VERSION "created by canmatrix"

NS_ :

BS_:

BU_: User ADM_PC_LL25 ADM_PC_BC25 ADM_PC_BP25 ADM_PC_BI25

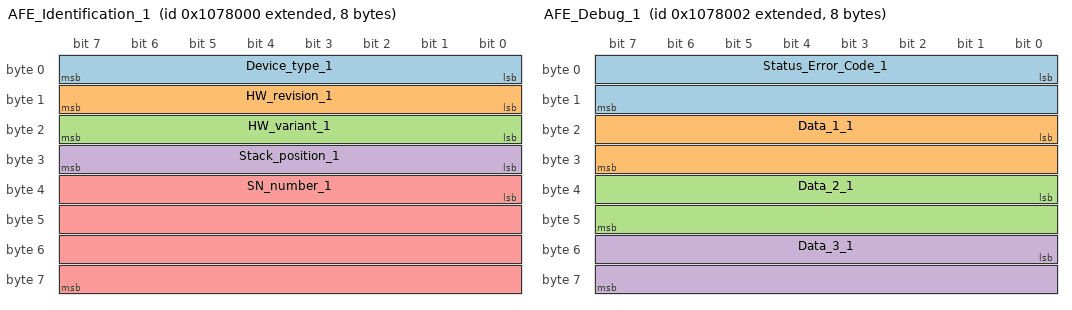
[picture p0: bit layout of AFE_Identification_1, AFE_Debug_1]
BO_ 2164752384 AFE_Identification_1: 8 ADM_PC_BP25
 SG_ Device_type_1 : 0|8@1+ (1,0) [0|255] "" Vector__XXX
 SG_ HW_revision_1 : 8|8@1+ (1,0) [0|255] "" Vector__XXX
 SG_ HW_variant_1 : 16|8@1+ (1,0) [0|255] "" Vector__XXX
 SG_ Stack_position_1 : 24|8@1+ (1,0) [0|255] "" Vector__XXX
 SG_ SN_number_1 : 32|32@1+ (1,0) [0|4294967295] "" Vector__XXX

BO_ 2164752385 AFE_FwInfo_1: 8 ADM_PC_BP25
 SG_ FW_info_mux_1 M : 56|8@1+ (1,0) [0|255] "" Vector__XXX
 SG_ FW_revision_0_1 m0 : 0|8@1+ (1,0) [0|255] "" Vector__XXX
 SG_ FW_revision_1_1 m0 : 8|8@1+ (1,0) [0|255] "" Vector__XXX
 SG_ FW_revision_2_1 m0 : 16|8@1+ (1,0) [0|255] "" Vector__XXX
 SG_ FW_revision_3_1 m0 : 24|8@1+ (1,0) [0|255] "" Vector__XXX
 SG_ FW_revision_4_1 m0 : 32|8@1+ (1,0) [0|255] "" Vector__XXX
 SG_ FW_revision_5_1 m0 : 40|8@1+ (1,0) [0|255] "" Vector__XXX
 SG_ FW_revision_6_1 m0 : 48|8@1+ (1,0) [0|255] "" Vector__XXX
 SG_ FW_revision_7_1 m1 : 0|8@1+ (1,0) [0|255] "" Vector__XXX
 SG_ FW_revision_8_1 m1 : 8|8@1+ (1,0) [0|255] "" Vector__XXX
 SG_ FW_revision_9_1 m1 : 16|8@1+ (1,0) [0|255] "" Vector__XXX
 SG_ FW_revision_10_1 m1 : 24|8@1+ (1,0) [0|255] "" Vector__XXX
 SG_ FW_revision_11_1 m1 : 32|8@1+ (1,0) [0|255] "" Vector__XXX
 SG_ FW_revision_12_1 m1 : 40|8@1+ (1,0) [0|255] "" Vector__XXX
 SG_ FW_revision_13_1 m1 : 48|8@1+ (1,0) [0|255] "" Vector__XXX
 SG_ FW_datecode_0_1 m2 : 0|8@1+ (1,0) [0|255] "" Vector__XXX
 SG_ FW_datecode_1_1 m2 : 8|8@1+ (1,0) [0|255] "" Vector__XXX
 SG_ FW_datecode_2_1 m2 : 16|8@1+ (1,0) [0|255] "" Vector__XXX
 SG_ FW_datecode_3_1 m2 : 24|8@1+ (1,0) [0|255] "" Vector__XXX
 SG_ FW_datecode_4_1 m2 : 32|8@1+ (1,0) [0|255] "" Vector__XXX
 SG_ FW_datecode_5_1 m2 : 40|8@1+ (1,0) [0|255] "" Vector__XXX
 SG_ FW_datecode_6_1 m2 : 48|8@1+ (1,0) [0|255] "" Vector__XXX
 SG_ FW_datecode_7_1 m3 : 0|8@1+ (1,0) [0|255] "" Vector__XXX
 SG_ FW_datecode_8_1 m3 : 8|8@1+ (1,0) [0|255] "" Vector__XXX
 SG_ FW_datecode_9_1 m3 : 16|8@1+ (1,0) [0|255] "" Vector__XXX
 SG_ FW_datecode_10_1 m3 : 24|8@1+ (1,0) [0|255] "" Vector__XXX
 SG_ FW_datecode_11_1 m3 : 32|8@1+ (1,0) [0|255] "" Vector__XXX
 SG_ FW_datecode_12_1 m3 : 40|8@1+ (1,0) [0|255] "" Vector__XXX
 SG_ FW_datecode_13_1 m3 : 48|8@1+ (1,0) [0|255] "" Vector__XXX

BO_ 2164752397 _AFE_Boot_FwInfo_1: 8 ADM_PC_BP25
 SG_ Boot_FW_info_mux_1 M : 56|8@1+ (1,0) [0|255] "" Vector__XXX
 SG_ FW_revision_0_1 m0 : 0|8@1+ (1,0) [0|255] "" Vector__XXX
 SG_ FW_revision_1_1 m0 : 8|8@1+ (1,0) [0|255] "" Vector__XXX
 SG_ FW_revision_2_1 m0 : 16|8@1+ (1,0) [0|255] "" Vector__XXX
 SG_ FW_revision_3_1 m0 : 24|8@1+ (1,0) [0|255] "" Vector__XXX
 SG_ FW_revision_4_1 m0 : 32|8@1+ (1,0) [0|255] "" Vector__XXX
 SG_ FW_revision_5_1 m0 : 40|8@1+ (1,0) [0|255] "" Vector__XXX
 SG_ FW_revision_6_1 m0 : 48|8@1+ (1,0) [0|255] "" Vector__XXX
 SG_ FW_revision_7_1 m1 : 0|8@1+ (1,0) [0|255] "" Vector__XXX
 SG_ FW_revision_8_1 m1 : 8|8@1+ (1,0) [0|255] "" Vector__XXX
 SG_ FW_revision_9_1 m1 : 16|8@1+ (1,0) [0|255] "" Vector__XXX
 SG_ FW_revision_10_1 m1 : 24|8@1+ (1,0) [0|255] "" Vector__XXX
 SG_ FW_revision_11_1 m1 : 32|8@1+ (1,0) [0|255] "" Vector__XXX
 SG_ FW_revision_12_1 m1 : 40|8@1+ (1,0) [0|255] "" Vector__XXX
 SG_ FW_revision_13_1 m1 : 48|8@1+ (1,0) [0|255] "" Vector__XXX
 SG_ FW_datecode_0_1 m2 : 0|8@1+ (1,0) [0|255] "" Vector__XXX
 SG_ FW_datecode_1_1 m2 : 8|8@1+ (1,0) [0|255] "" Vector__XXX
 SG_ FW_datecode_2_1 m2 : 16|8@1+ (1,0) [0|255] "" Vector__XXX
 SG_ FW_datecode_3_1 m2 : 24|8@1+ (1,0) [0|255] "" Vector__XXX
 SG_ FW_datecode_4_1 m2 : 32|8@1+ (1,0) [0|255] "" Vector__XXX
 SG_ FW_datecode_5_1 m2 : 40|8@1+ (1,0) [0|255] "" Vector__XXX
 SG_ FW_datecode_6_1 m2 : 48|8@1+ (1,0) [0|255] "" Vector__XXX
 SG_ FW_datecode_7_1 m3 : 0|8@1+ (1,0) [0|255] "" Vector__XXX
 SG_ FW_datecode_8_1 m3 : 8|8@1+ (1,0) [0|255] "" Vector__XXX
 SG_ FW_datecode_9_1 m3 : 16|8@1+ (1,0) [0|255] "" Vector__XXX
 SG_ FW_datecode_10_1 m3 : 24|8@1+ (1,0) [0|255] "" Vector__XXX
 SG_ FW_datecode_11_1 m3 : 32|8@1+ (1,0) [0|255] "" Vector__XXX
 SG_ FW_datecode_12_1 m3 : 40|8@1+ (1,0) [0|255] "" Vector__XXX
 SG_ FW_datecode_13_1 m3 : 48|8@1+ (1,0) [0|255] "" Vector__XXX

BO_ 2164752386 AFE_Debug_1: 8 ADM_PC_BP25
 SG_ Status_Error_Code_1 : 0|16@1+ (1,0) [0|65535] "" Vector__XXX
 SG_ Data_1_1 : 16|16@1+ (1,0) [0|65535] "" Vector__XXX
 SG_ Data_2_1 : 32|16@1+ (1,0) [0|65535] "" Vector__XXX
 SG_ Data_3_1 : 48|16@1+ (1,0) [0|65535] "" Vector__XXX

BO_ 2164752391 AFE_Status_1: 8 ADM_PC_BP25
 SG_ Running_1 : 0|1@1+ (1,0) [0|1] "" Vector__XXX
 SG_ PWM_1 : 1|1@1+ (1,0) [0|1] "" Vector__XXX
 SG_ Current_dc_loop_mode_1 : 2|1@1+ (1,0) [0|1] "" Vector__XXX
 SG_ Current_ac_loop_mode_1 : 3|1@1+ (1,0) [0|1] "" Vector__XXX
 SG_ Buck_1 : 5|1@1+ (1,0) [0|1] "" Vector__XXX
 SG_ Boost_1 : 6|1@1+ (1,0) [0|1] "" Vector__XXX
 SG_ Precharge_dc_buck_mode_1 : 7|1@1+ (1,0) [0|1] "" Vector__XXX
 SG_ Precharge_dc_boost_mode_1 : 8|1@1+ (1,0) [0|1] "" Vector__XXX
 SG_ Rectifier_3ph_1 : 9|1@1+ (1,0) [0|1] "" Vector__XXX
 SG_ Stack_mode_1 : 10|1@1+ (1,0) [0|1] "" Vector__XXX
 SG_ Master_1 : 11|1@1+ (1,0) [0|1] "" Vector__XXX
 SG_ Slave_1 : 12|1@1+ (1,0) [0|1] "" Vector__XXX
 SG_ Inverter_1ph_1 : 13|1@1+ (1,0) [0|1] "" Vector__XXX
 SG_ Boost_Neutral_1 : 14|1@1+ (1,0) [0|1] "" Vector__XXX
 SG_ Rectifier_1ph_1 : 15|1@1+ (1,0) [0|1] "" Vector__XXX
 SG_ Inverter_3ph_1 : 16|1@1+ (1,0) [0|1] "" Vector__XXX
 SG_ Ready_1 : 17|1@1+ (1,0) [0|1] "" Vector__XXX
 SG_ Inverter_1ph_Sync_1 : 18|1@1+ (1,0) [0|1] "" Vector__XXX
 SG_ Neutral_1 : 19|1@1+ (1,0) [0|1] "" Vector__XXX
 SG_ Rectifier_1ph_Buck_1 : 20|1@1+ (1,0) [0|1] "" Vector__XXX
 SG_ Inverter_1ph_Boost_1 : 21|1@1+ (1,0) [0|1] "" Vector__XXX
 SG_ Rectifier_distributed_1 : 22|1@1+ (1,0) [0|1] "" Vector__XXX
 SG_ MPPT_buck_1 : 23|1@1+ (1,0) [0|1] "" Vector__XXX
 SG_ MPPT_boost_1 : 24|1@1+ (1,0) [0|1] "" Vector__XXX
 SG_ Buck_2p_float_1 : 25|1@1+ (1,0) [0|1] "" Vector__XXX
 SG_ Inverter_1ph_Distributed_1 : 26|1@1+ (1,0) [0|1] "" Vector__XXX

BO_ 2164752390 AFE_Faults_1: 3 ADM_PC_BP25
 SG_ Protection_trip_internal_1 : 0|1@1+ (1,0) [0|1] "" Vector__XXX
 SG_ Protection_trip_external_1 : 1|1@1+ (1,0) [0|1] "" Vector__XXX
 SG_ Phase_U_overcurrent_1 : 2|1@1+ (1,0) [0|1] "" Vector__XXX
 SG_ Phase_U_overvoltage_1 : 3|1@1+ (1,0) [0|1] "" Vector__XXX
 SG_ Phase_U_undervoltage_1 : 4|1@1+ (1,0) [0|1] "" Vector__XXX
 SG_ Phase_V_overvoltage_1 : 5|1@1+ (1,0) [0|1] "" Vector__XXX
 SG_ Phase_V_undervoltage_1 : 6|1@1+ (1,0) [0|1] "" Vector__XXX
 SG_ Phase_V_overcurrent_1 : 7|1@1+ (1,0) [0|1] "" Vector__XXX
 SG_ Phase_W_overvoltage_1 : 8|1@1+ (1,0) [0|1] "" Vector__XXX
 SG_ Phase_W_undervoltage_1 : 9|1@1+ (1,0) [0|1] "" Vector__XXX
 SG_ Phase_W_overcurrent_1 : 10|1@1+ (1,0) [0|1] "" Vector__XXX
 SG_ DC_undervoltage_1 : 11|1@1+ (1,0) [0|1] "" Vector__XXX
 SG_ DC_overvoltage_1 : 12|1@1+ (1,0) [0|1] "" Vector__XXX
 SG_ MOSFET_overtemperature_1 : 13|1@1+ (1,0) [0|1] "" Vector__XXX
 SG_ Inductor_overtemperature_1 : 14|1@1+ (1,0) [0|1] "" Vector__XXX
 SG_ Keep_Alive_not_served_1 : 15|1@1+ (1,0) [0|1] "" Vector__XXX
 SG_ PLL_not_locked_1 : 16|1@1+ (1,0) [0|1] "" Vector__XXX
 SG_ NFO_1 : 20|1@1+ (1,0) [0|1] "" Vector__XXX
 SG_ Measurement_system_failure_1 : 21|1@1+ (1,0) [0|1] "" Vector__XXX
 SG_ EEPROM_failure_1 : 22|1@1+ (1,0) [0|1] "" Vector__XXX
 SG_ System_1 : 23|1@1+ (1,0) [0|1] "" Vector__XXX

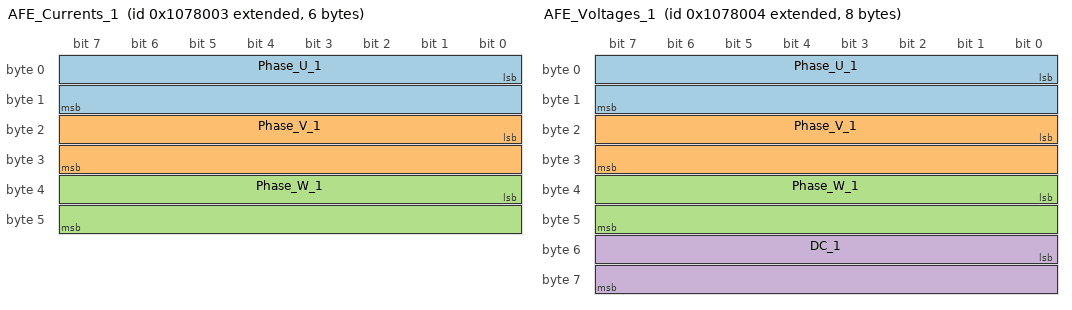
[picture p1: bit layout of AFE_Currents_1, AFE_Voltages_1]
BO_ 2164752387 AFE_Currents_1: 6 ADM_PC_BP25
 SG_ Phase_U_1 : 0|16@1- (0.01,0) [-327.68|327.67] "A" Vector__XXX
 SG_ Phase_V_1 : 16|16@1- (0.01,0) [-327.68|327.67] "A" Vector__XXX
 SG_ Phase_W_1 : 32|16@1- (0.01,0) [-327.68|327.67] "A" Vector__XXX

BO_ 2164752400 AFE_DC_Bus_current_1: 2 ADM_PC_BP25
 SG_ Bus_current_1 : 0|16@1- (0.01,0) [-327.68|327.67] "A" Vector__XXX

BO_ 2164752398 _AFE_Broadcast_1: 8 ADM_PC_BP25
 SG_ Diagnostics_Index_1 M : 56|8@1+ (1,0) [0|255] "" Vector__XXX
 SG_ Phase_U_1 m1 : 8|16@1- (0.01,0) [-327.68|327.67] "A" ADM_PC_BP25
 SG_ Phase_V_1 m1 : 24|16@1- (0.01,0) [-327.68|327.67] "A" ADM_PC_BP25
 SG_ Phase_W_1 m1 : 40|16@1- (0.01,0) [-327.68|327.67] "A" ADM_PC_BP25
 SG_ Stack_position_1 : 0|5@1+ (1,0) [0|31] "" ADM_PC_BP25
 SG_ Group_ID_1 : 5|3@1+ (1,0) [0|7] "" ADM_PC_BP25

BO_ 2164752388 AFE_Voltages_1: 8 ADM_PC_BP25
 SG_ Phase_U_1 : 0|16@1- (0.1,0) [-3276.8|3276.7] "V" Vector__XXX
 SG_ Phase_V_1 : 16|16@1- (0.1,0) [-3276.8|3276.7] "V" Vector__XXX
 SG_ Phase_W_1 : 32|16@1- (0.1,0) [-3276.8|3276.7] "V" Vector__XXX
 SG_ DC_1 : 48|16@1- (0.1,0) [-3276.8|3276.7] "V" Vector__XXX

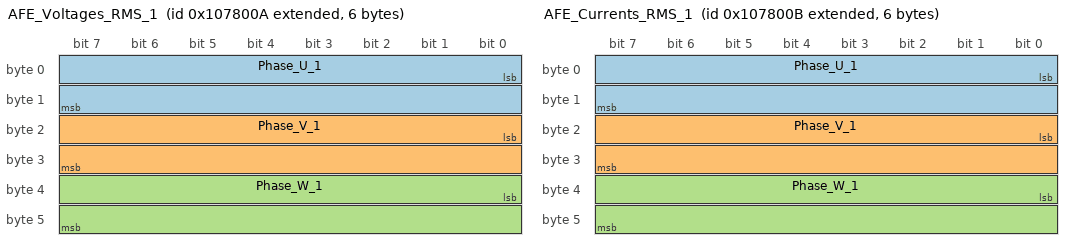
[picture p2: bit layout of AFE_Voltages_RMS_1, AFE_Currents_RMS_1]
BO_ 2164752394 AFE_Voltages_RMS_1: 6 ADM_PC_BP25
 SG_ Phase_U_1 : 0|16@1+ (0.1,0) [0|6553.5] "V" Vector__XXX
 SG_ Phase_V_1 : 16|16@1+ (0.1,0) [0|6553.5] "V" Vector__XXX
 SG_ Phase_W_1 : 32|16@1+ (0.1,0) [0|6553.5] "V" Vector__XXX

BO_ 2164752395 AFE_Currents_RMS_1: 6 ADM_PC_BP25
 SG_ Phase_U_1 : 0|16@1+ (0.01,0) [0.00|655.35] "A" Vector__XXX
 SG_ Phase_V_1 : 16|16@1+ (0.01,0) [0.00|655.35] "A" Vector__XXX
 SG_ Phase_W_1 : 32|16@1+ (0.01,0) [0.00|655.35] "A" Vector__XXX

BO_ 2164752396 AFE_Mains_1: 4 ADM_PC_BP25
 SG_ Frequency_1 : 0|16@1+ (0.01,0) [0.00|655.35] "Hz" Vector__XXX
 SG_ Phase_1 : 16|16@1- (0.1,0) [-3276.8|3276.7] "Deg." Vector__XXX

BO_ 2164752389 AFE_Temperatures_1: 4 ADM_PC_BP25
 SG_ Temp_Bridge_1 : 0|16@1- (0.01,0) [-327.68|327.67] "°C" Vector__XXX
 SG_ Temp_Inductors_1 : 16|16@1- (0.01,0) [-327.68|327.67] "°C" Vector__XXX

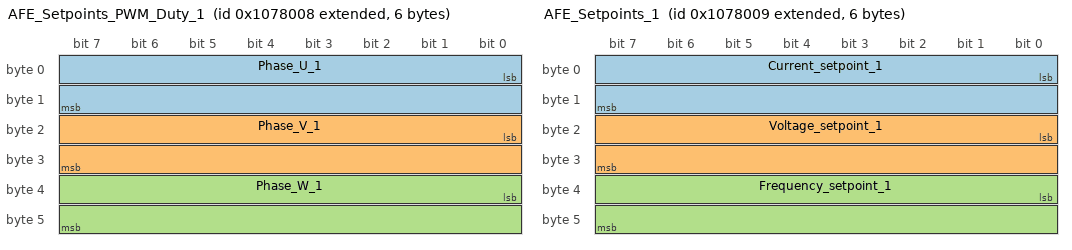
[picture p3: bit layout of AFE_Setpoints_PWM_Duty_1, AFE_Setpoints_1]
BO_ 2164752392 AFE_Setpoints_PWM_Duty_1: 6 ADM_PC_BP25
 SG_ Phase_U_1 : 0|16@1+ (0.001525902,0) [0E-009|99.999987570] "%" Vector__XXX
 SG_ Phase_V_1 : 16|16@1+ (0.001525902,0) [0E-009|99.999987570] "%" Vector__XXX
 SG_ Phase_W_1 : 32|16@1+ (0.001525902,0) [0E-009|99.999987570] "%" Vector__XXX

BO_ 2164752393 AFE_Setpoints_1: 6 ADM_PC_BP25
 SG_ Current_setpoint_1 : 0|16@1- (0.01,0) [-327.68|327.67] "A" Vector__XXX
 SG_ Voltage_setpoint_1 : 16|16@1+ (0.1,0) [0|6553.5] "V" Vector__XXX
 SG_ Frequency_setpoint_1 : 32|16@1+ (0.01,0) [0.00|655.35] "Hz" Vector__XXX

BO_ 2164719712 AFE_Keep_Alive_1: 1 User
 SG_ Keep_Alive_Enable_1 : 0|1@1+ (1,0) [0|1] "" ADM_PC_BP25

BO_ 2164719680 AFE_Mode_Control_1: 8 User
 SG_ Converter_ON_1 : 0|1@1+ (1,0) [0|1] "" ADM_PC_BP25
 SG_ PWM_ON_1 : 1|1@1+ (1,0) [0|1] "" ADM_PC_BP25
 SG_ DC_Current_feedback_ON_1 : 2|1@1+ (1,0) [0|1] "" ADM_PC_BP25
 SG_ AC_Current_feedback_ON_1 : 3|1@1+ (1,0) [0|1] "" ADM_PC_BP25
 SG_ Buck_ON_1 : 5|1@1+ (1,0) [0|1] "" ADM_PC_BP25
 SG_ Boost_ON_1 : 6|1@1+ (1,0) [0|1] "" ADM_PC_BP25
 SG_ Rectifier_3ph_ON_1 : 9|1@1+ (1,0) [0|1] "" ADM_PC_BP25
 SG_ Inverter_1ph_ON_1 : 10|1@1+ (1,0) [0|1] "" ADM_PC_BP25
 SG_ Rectifier_1ph_ON_1 : 11|1@1+ (1,0) [0|1] "" ADM_PC_BP25
 SG_ Boost_Neutral_ON_1 : 12|1@1+ (1,0) [0|1] "" ADM_PC_BP25
 SG_ Inverter_3ph_ON_1 : 13|1@1+ (1,0) [0|1] "" ADM_PC_BP25
 SG_ Inverter_1ph_Sync_ON_1 : 14|1@1+ (1,0) [0|1] "" ADM_PC_BP25
 SG_ Neutral_ON_1 : 15|1@1+ (1,0) [0|1] "" ADM_PC_BP25
 SG_ Rectifier_1ph_Buck_ON_1 : 16|1@1+ (1,0) [0|1] "" ADM_PC_BP25
 SG_ Inverter_1ph_Boost_ON_1 : 17|1@1+ (1,0) [0|1] "" ADM_PC_BP25
 SG_ Rectifier_Distributed_ON_1 : 18|1@1+ (1,0) [0|1] "" ADM_PC_BP25
 SG_ MPPT_buck_ON_1 : 19|1@1+ (1,0) [0|1] "" ADM_PC_BP25
 SG_ MPPT_boost_ON_1 : 20|1@1+ (1,0) [0|1] "" ADM_PC_BP25
 SG_ Buck_2p_float_ON_1 : 21|1@1+ (1,0) [0|1] "" ADM_PC_BP25
 SG_ Inverter_1ph_Distributed_ON_1 : 22|1@1+ (1,0) [0|1] "" ADM_PC_BP25

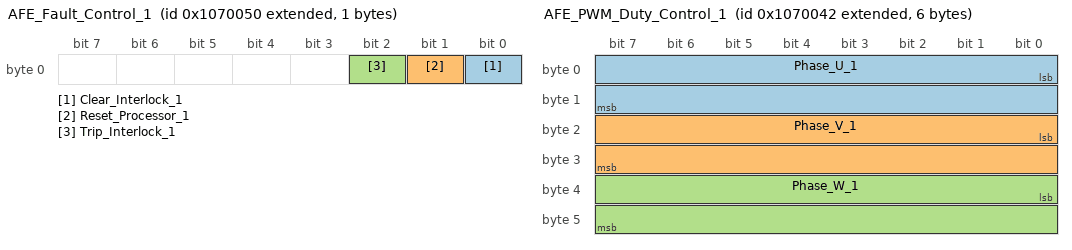
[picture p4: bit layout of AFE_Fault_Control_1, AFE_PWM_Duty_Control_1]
BO_ 2164719696 AFE_Fault_Control_1: 1 User
 SG_ Clear_Interlock_1 : 0|1@1+ (1,0) [0|1] "" ADM_PC_BP25
 SG_ Reset_Processor_1 : 1|1@1+ (1,0) [0|1] "" ADM_PC_BP25
 SG_ Trip_Interlock_1 : 2|1@1+ (1,0) [0|1] "" ADM_PC_BP25

BO_ 2164719681 AFE_Reactive_Current_Setpoint_Co: 2 User
 SG_ Reactive_current_setpoint_1 : 0|16@1- (0.01,0) [-150|150] "A" ADM_PC_BP25

BO_ 2164719682 AFE_PWM_Duty_Control_1: 6 User
 SG_ Phase_U_1 : 0|16@1+ (0.001525902,0) [0E-009|99.999987570] "%" ADM_PC_BP25
 SG_ Phase_V_1 : 16|16@1+ (0.001525902,0) [0E-009|99.999987570] "%" ADM_PC_BP25
 SG_ Phase_W_1 : 32|16@1+ (0.001525902,0) [0E-009|99.999987570] "%" ADM_PC_BP25

BO_ 2164719683 AFE_Current_Setpoint_Control_1: 2 User
 SG_ Current_setpoint_1 : 0|16@1- (0.01,0) [-150|150] "A" ADM_PC_BP25

BO_ 2164719684 AFE_Voltage_Setpoint_Control_1: 2 User
 SG_ Voltage_setpoint_1 : 0|16@1+ (0.1,0) [0|1500] "V" ADM_PC_BP25

BO_ 2164719688 AFE_Frequency_Setpoint_Control_1: 2 User
 SG_ Frequency_setpoint_1 : 0|16@1+ (0.01,0) [40|70] "Hz" ADM_PC_BP25

BO_ 2164719689 AFE_Phase_Setpoint_Control_1: 2 User
 SG_ Phase_setpoint_1 : 0|16@1+ (1,0) [0|360] "deg" ADM_PC_BP25

BO_ 2164719728 AFE_Rectifier_Setpoint_Control_1: 8 User
 SG_ Voltage_setpoint_2_1 : 0|16@1+ (0.1,0) [0|1500] "V" ADM_PC_BP25
 SG_ Current_setpoint_2_1 : 16|16@1- (0.01,0) [-150|150] "A" ADM_PC_BP25

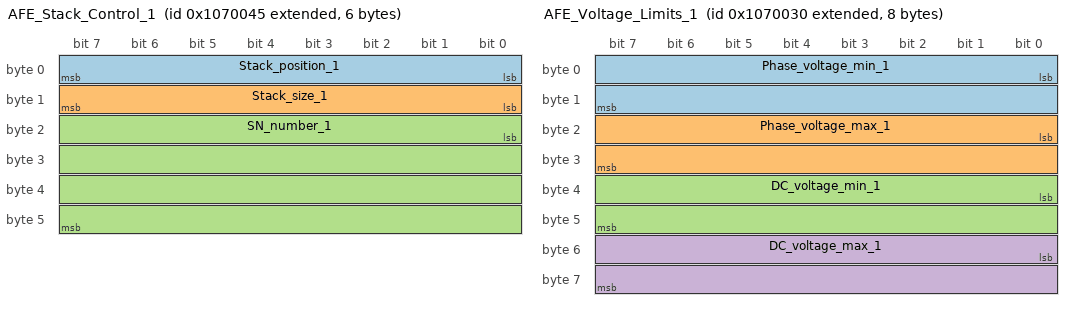
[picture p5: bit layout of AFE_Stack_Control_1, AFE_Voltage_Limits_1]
BO_ 2164719685 AFE_Stack_Control_1: 6 User
 SG_ Stack_position_1 : 0|8@1+ (1,0) [0|255] "" ADM_PC_BP25
 SG_ Stack_size_1 : 8|8@1+ (1,0) [0|255] "" ADM_PC_BP25
 SG_ SN_number_1 : 16|32@1+ (1,0) [0|4294967295] "" ADM_PC_BP25

BO_ 2164719664 AFE_Voltage_Limits_1: 8 User
 SG_ Phase_voltage_min_1 : 0|16@1- (0.1,0) [0|3276.7] "V" ADM_PC_BP25
 SG_ Phase_voltage_max_1 : 16|16@1- (0.1,0) [-3276.8|850] "V" ADM_PC_BP25
 SG_ DC_voltage_min_1 : 32|16@1- (0.1,0) [0|3276.7] "V" ADM_PC_BP25
 SG_ DC_voltage_max_1 : 48|16@1- (0.1,0) [-3276.8|850] "V" ADM_PC_BP25

BO_ 2164719665 AFE_Current_Limits_1: 4 User
 SG_ Phase_current_min_1 : 0|16@1- (0.01,0) [-60|60] "A" ADM_PC_BP25
 SG_ Phase_current_max_1 : 16|16@1- (0.01,0) [-60|60] "A" ADM_PC_BP25

BO_ 2164719692 AFE_Group_Control_1: 1 User
 SG_ Group_ID_1 : 0|8@1+ (1,0) [0|255] "" ADM_PC_BP25

BO_ 2164752399 AFE_Group_Info_1: 1 ADM_PC_BP25
 SG_ Group_ID_1 : 0|8@1+ (1,0) [0|255] "" Vector__XXX

BO_ 2164719713 AFE_System_Flags_Control_1: 8 User
 SG_ Factory_mode_1 : 0|1@1+ (1,0) [0|1] "" ADM_PC_BP25
 SG_ Silent_CAN_mode_1 : 1|1@1+ (1,0) [0|1] "" ADM_PC_BP25

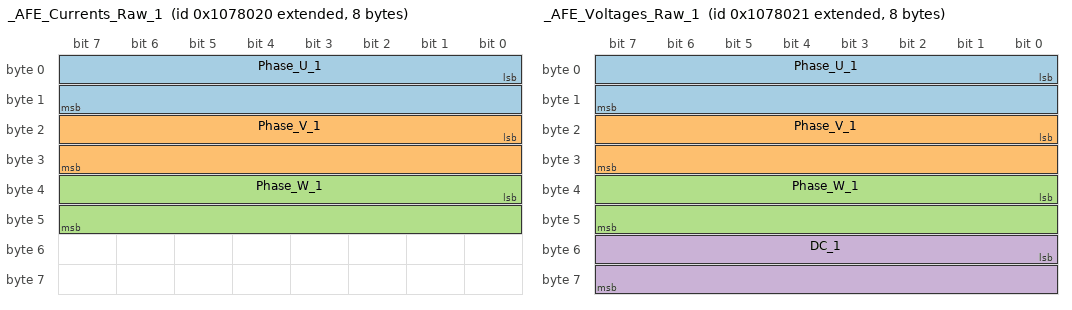
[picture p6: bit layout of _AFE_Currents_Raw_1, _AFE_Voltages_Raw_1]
BO_ 2164752416 _AFE_Currents_Raw_1: 8 ADM_PC_BP25
 SG_ Phase_U_1 : 0|16@1- (1,0) [-32768|32767] "" Vector__XXX
 SG_ Phase_V_1 : 16|16@1- (1,0) [-32768|32767] "" Vector__XXX
 SG_ Phase_W_1 : 32|16@1- (1,0) [-32768|32767] "" Vector__XXX

BO_ 2164752417 _AFE_Voltages_Raw_1: 8 ADM_PC_BP25
 SG_ Phase_U_1 : 0|16@1- (1,0) [-32768|32767] "" Vector__XXX
 SG_ Phase_V_1 : 16|16@1- (1,0) [-32768|32767] "" Vector__XXX
 SG_ Phase_W_1 : 32|16@1- (1,0) [-32768|32767] "" Vector__XXX
 SG_ DC_1 : 48|16@1- (1,0) [-32768|32767] "" Vector__XXX

BO_ 2164719690 _AFE_ADC_Calibration_Mode_1: 1 User
 SG_ Calibration_Index_1 M : 2|5@1+ (1,0) [0|31] "" Vector__XXX
 SG_ Current_U_1 m1 : 0|2@1+ (1,0) [0|3] "" ADM_PC_BP25
 SG_ Current_V_1 m2 : 0|2@1+ (1,0) [0|3] "" ADM_PC_BP25
 SG_ Current_W_1 m3 : 0|2@1+ (1,0) [0|3] "" ADM_PC_BP25
 SG_ Voltage_U_1 m4 : 0|2@1+ (1,0) [0|3] "" ADM_PC_BP25
 SG_ Voltage_V_1 m5 : 0|2@1+ (1,0) [0|3] "" ADM_PC_BP25
 SG_ Voltage_W_1 m6 : 0|2@1+ (1,0) [0|3] "" ADM_PC_BP25
 SG_ Voltage_DC_1 m7 : 0|2@1+ (1,0) [0|3] "" ADM_PC_BP25
 SG_ start_1 : 7|1@1+ (1,0) [0|1] "" ADM_PC_BP25

BO_ 2164719691 _AFE_ADC_Calibration_Setpoint_1: 3 User
 SG_ Calibration_Index_1 M : 16|5@1+ (1,0) [0|31] "" Vector__XXX
 SG_ Current_U_1 m1 : 0|16@1- (0.01,0) [-100|100] "A" ADM_PC_BP25
 SG_ Current_V_1 m2 : 0|16@1- (0.01,0) [-100|100] "A" ADM_PC_BP25
 SG_ Current_W_1 m3 : 0|16@1- (0.01,0) [-100|100] "A" ADM_PC_BP25
 SG_ Voltage_U_1 m4 : 0|16@1+ (0.1,0) [0|1500] "V" ADM_PC_BP25
 SG_ Voltage_V_1 m5 : 0|16@1+ (0.1,0) [0|1500] "V" ADM_PC_BP25
 SG_ Voltage_W_1 m6 : 0|16@1+ (0.1,0) [0|1500] "V" ADM_PC_BP25
 SG_ Voltage_DC_1 m7 : 0|16@1+ (0.1,0) [0|1500] "V" ADM_PC_BP25
 SG_ point_1 : 21|3@1+ (1,0) [0|7] "" ADM_PC_BP25

BO_ 2164719686 _AFE_Calibration_Offset_Update_1: 6 User
 SG_ Calibration_Index_1 M : 16|16@1+ (1,0) [0|65535] "" Vector__XXX
 SG_ Current_U_1 m0 : 0|16@1- (1,0) [-32768|32767] "ADC Counts" ADM_PC_BP25
 SG_ Current_V_1 m1 : 0|16@1- (1,0) [-32768|32767] "ADC Counts" ADM_PC_BP25
 SG_ Current_W_1 m2 : 0|16@1- (1,0) [-32768|32767] "ADC Counts" ADM_PC_BP25
 SG_ Voltage_U_1 m3 : 0|16@1- (1,0) [-32768|32767] "ADC Counts" ADM_PC_BP25
 SG_ Voltage_V_1 m4 : 0|16@1- (1,0) [-32768|32767] "ADC Counts" ADM_PC_BP25
 SG_ Voltage_W_1 m5 : 0|16@1- (1,0) [-32768|32767] "ADC Counts" ADM_PC_BP25
 SG_ Voltage_DC_1 m6 : 0|16@1- (1,0) [-32768|32767] "ADC Counts" ADM_PC_BP25
 SG_ CRC_1 : 32|16@1+ (1,0) [0|65535] "-" ADM_PC_BP25

BO_ 2164719687 _AFE_Calibration_Scale_Update_1: 6 User
 SG_ Calibration_Index_1 M : 16|16@1+ (1,0) [0|65535] "" Vector__XXX
 SG_ Current_U_1 m0 : 0|16@1- (0.0000152587890625,0) [-0.5000000000000000|0.4999847412109375] "scale = 1.0 + value" ADM_PC_BP25
 SG_ Current_V_1 m1 : 0|16@1- (0.0000152587890625,0) [-0.5000000000000000|0.4999847412109375] "scale = 1.0 + value" ADM_PC_BP25
 SG_ Current_W_1 m2 : 0|16@1- (0.0000152587890625,0) [-0.5000000000000000|0.4999847412109375] "scale = 1.0 + value" ADM_PC_BP25
 SG_ Voltage_U_1 m3 : 0|16@1- (0.0000152587890625,0) [-0.5000000000000000|0.4999847412109375] "scale = 1.0 + value" ADM_PC_BP25
 SG_ Voltage_V_1 m4 : 0|16@1- (0.0000152587890625,0) [-0.5000000000000000|0.4999847412109375] "scale = 1.0 + value" ADM_PC_BP25
 SG_ Voltage_W_1 m5 : 0|16@1- (0.0000152587890625,0) [-0.5000000000000000|0.4999847412109375] "scale = 1.0 + value" ADM_PC_BP25
 SG_ Voltage_DC_1 m6 : 0|16@1- (0.0000152587890625,0) [-0.5000000000000000|0.4999847412109375] "scale = 1.0 + value" ADM_PC_BP25
 SG_ CRC_1 : 32|16@1+ (1,0) [0|65535] "-" ADM_PC_BP25

BO_ 2164752465 _AFE_Calibration_Adc_Scale_1: 6 ADM_PC_BP25
 SG_ Adc_Index_1 M : 32|16@1+ (1,0) [0|65535] "" Vector__XXX
 SG_ Current_U_1 m0 : 0|32@1+ (1,0) [0|4294967295] "1 / adc_bins" User
 SG_ Current_V_1 m1 : 0|32@1+ (1,0) [0|4294967295] "1 / adc_bins" User
 SG_ Current_W_1 m2 : 0|32@1+ (1,0) [0|4294967295] "1 / adc_bins" User
 SG_ Voltage_U_1 m3 : 0|32@1+ (1,0) [0|4294967295] "1 / adc_bins" User
 SG_ Voltage_V_1 m4 : 0|32@1+ (1,0) [0|4294967295] "1 / adc_bins" User
 SG_ Voltage_W_1 m5 : 0|32@1+ (1,0) [0|4294967295] "1 / adc_bins" User
 SG_ Voltage_DC_1 m6 : 0|32@1+ (1,0) [0|4294967295] "1 / adc_bins" User

BO_ 2164752466 _AFE_Calibration_Adc_Fs_1: 6 ADM_PC_BP25
 SG_ Adc_Index_1 M : 32|16@1+ (1,0) [0|65535] "" Vector__XXX
 SG_ Current_U_1 m0 : 0|32@1+ (1,0) [0|4294967295] "Fullscale" User
 SG_ Current_V_1 m1 : 0|32@1+ (1,0) [0|4294967295] "Fullscale" User
 SG_ Current_W_1 m2 : 0|32@1+ (1,0) [0|4294967295] "Fullscale" User
 SG_ Voltage_U_1 m3 : 0|32@1+ (1,0) [0|4294967295] "Fullscale" User
 SG_ Voltage_V_1 m4 : 0|32@1+ (1,0) [0|4294967295] "Fullscale" User
 SG_ Voltage_W_1 m5 : 0|32@1+ (1,0) [0|4294967295] "Fullscale" User
 SG_ Voltage_DC_1 m6 : 0|32@1+ (1,0) [0|4294967295] "Fullscale" User

BO_ 2164752467 _AFE_Calibration_Adc_Offset_1: 4 ADM_PC_BP25
 SG_ Adc_Index_1 M : 16|16@1+ (1,0) [0|65535] "" Vector__XXX
 SG_ Current_U_1 m0 : 0|16@1- (1,0) [-32768|32767] "-" User
 SG_ Current_V_1 m1 : 0|16@1- (1,0) [-32768|32767] "-" User
 SG_ Current_W_1 m2 : 0|16@1- (1,0) [-32768|32767] "-" User
 SG_ Voltage_U_1 m3 : 0|16@1- (1,0) [-32768|32767] "-" User
 SG_ Voltage_V_1 m4 : 0|16@1- (1,0) [-32768|32767] "-" User
 SG_ Voltage_W_1 m5 : 0|16@1- (1,0) [-32768|32767] "-" User
 SG_ Voltage_DC_1 m6 : 0|16@1- (1,0) [-32768|32767] "-" User

BO_ 2164752468 _AFE_Calibration_Adc_Gain_1: 4 ADM_PC_BP25
 SG_ Adc_Index_1 M : 16|16@1+ (1,0) [0|65535] "" Vector__XXX
 SG_ Current_U_1 m0 : 0|16@1- (1,0) [-32768|32767] "-" User
 SG_ Current_V_1 m1 : 0|16@1- (1,0) [-32768|32767] "-" User
 SG_ Current_W_1 m2 : 0|16@1- (1,0) [-32768|32767] "-" User
 SG_ Voltage_U_1 m3 : 0|16@1- (1,0) [-32768|32767] "-" User
 SG_ Voltage_V_1 m4 : 0|16@1- (1,0) [-32768|32767] "-" User
 SG_ Voltage_W_1 m5 : 0|16@1- (1,0) [-32768|32767] "-" User
 SG_ Voltage_DC_1 m6 : 0|16@1- (1,0) [-32768|32767] "-" User

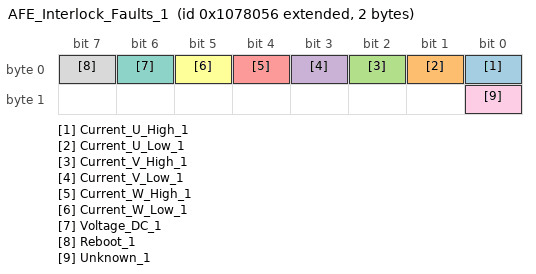
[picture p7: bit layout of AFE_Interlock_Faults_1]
BO_ 2164752470 AFE_Interlock_Faults_1: 2 ADM_PC_BP25
 SG_ Current_U_High_1 : 0|1@1+ (1,0) [0|1] "" Vector__XXX
 SG_ Current_U_Low_1 : 1|1@1+ (1,0) [0|1] "" Vector__XXX
 SG_ Current_V_High_1 : 2|1@1+ (1,0) [0|1] "" Vector__XXX
 SG_ Current_V_Low_1 : 3|1@1+ (1,0) [0|1] "" Vector__XXX
 SG_ Current_W_High_1 : 4|1@1+ (1,0) [0|1] "" Vector__XXX
 SG_ Current_W_Low_1 : 5|1@1+ (1,0) [0|1] "" Vector__XXX
 SG_ Voltage_DC_1 : 6|1@1+ (1,0) [0|1] "" Vector__XXX
 SG_ Reboot_1 : 7|1@1+ (1,0) [0|1] "" Vector__XXX
 SG_ Unknown_1 : 8|1@1+ (1,0) [0|1] "" Vector__XXX

BO_TX_BU_ 2164719680 : User,ADM_PC_LL25,ADM_PC_BC25,ADM_PC_BI25;
BO_TX_BU_ 2164719683 : User,ADM_PC_LL25,ADM_PC_BC25,ADM_PC_BI25;
BO_TX_BU_ 2164719684 : User,ADM_PC_LL25,ADM_PC_BC25,ADM_PC_BI25;
CM_ BO_ 2164752384  "Identification of the device";
CM_ BO_ 2164752385  "Git revision of the DSP firmware";
CM_ BO_ 2164752397  "Git revision of the bootloader firmware.";
CM_ BO_ 2164752386  "Values for debugging of HW/SW problems";
CM_ BO_ 2164752391  "Status bitfield";
CM_ BO_ 2164752390  "Fault bitfield";
CM_ BO_ 2164752387  "Current of phases U, V, W";
CM_ BO_ 2164752400  "Current of of the DC Bus";
CM_ BO_ 2164752398  "All AFEs will listen to this message";
CM_ BO_ 2164752395  "RMS Current of phases U, V, W";
CM_ BO_ 2164752396  "Three-Phase mains health (frequency, phase...)";
CM_ BO_ 2164752389  "Readouts of the module temperature sensors";
CM_ BO_ 2164752392  "Setpoints";
CM_ BO_ 2164752393  "Setpoints";
CM_ BO_ 2164719712  "Keep alive ping message. ";
CM_ BO_ 2164719680  "Operation Mode control: sets the converter operation mode";
CM_ BO_ 2164719696  "Fault Control: actions to clear faults and reset the system";
CM_ BO_ 2164719681  "Reactive power setpoint control.";
CM_ BO_ 2164719682  "PWM duty cycle control";
CM_ BO_ 2164719683  "Current setpoint control";
CM_ BO_ 2164719684  "Voltage setpoint control";
CM_ BO_ 2164719688  "Frequency setpoint control";
CM_ BO_ 2164719689  "Phase setpoint control";
CM_ BO_ 2164719728  "Additional voltage and current setpoints in single-phase rectifier and inverter control modes.";
CM_ BO_ 2164719685  "PFC stack control";
CM_ BO_ 2164719664  "Set the input and output voltage limits (minimum and maximum)";
CM_ BO_ 2164719665  "Set the output current limits (mminimum and maximum)";
CM_ BO_ 2164719692  "Set the Group ID of the device";
CM_ BO_ 2164752399  "Contains the Group ID of the device";
CM_ BO_ 2164719713  "Control the system flags";
CM_ BO_ 2164752416  "Current of phases A and B";
CM_ BO_ 2164752417  "Current of phases A and B";
CM_ BO_ 2164719690  "Automatic ADC calibration.";
CM_ BO_ 2164719691  "Setpoint for automatic ADC calibration.";
CM_ BO_ 2164719686  "Update of the calibration table for offsets.";
CM_ BO_ 2164719687  "Update of the calibration table for scales.";
CM_ BO_ 2164752465  "
                Adc scale (resolution) value of readouts.
            ";
CM_ BO_ 2164752466  "
                Adc fullscale value of readouts.
            ";
CM_ BO_ 2164752467  "
                Readout of ADC calibration data (offset) from EEPROM.
            ";
CM_ BO_ 2164752468  "
                Readout of ADC calibration data (gain) from EEPROM.
            ";
CM_ BO_ 2164752470  "Fault bitfield";

CM_ SG_ 2164752384 Device_type_1 "The device identification field, uniquely identifies the sender in the network";
CM_ SG_ 2164752384 HW_revision_1 "The hardware revision number";
CM_ SG_ 2164752384 HW_variant_1 "The DSP firmware revision number";
CM_ SG_ 2164752384 Stack_position_1 "Position of the module within the stack";
CM_ SG_ 2164752384 SN_number_1 "Unique module serial number";
CM_ SG_ 2164752385 FW_revision_0_1 "Character 0";
CM_ SG_ 2164752385 FW_revision_1_1 "Character 1";
CM_ SG_ 2164752385 FW_revision_2_1 "Character 2";
CM_ SG_ 2164752385 FW_revision_3_1 "Character 3";
CM_ SG_ 2164752385 FW_revision_4_1 "Character 3";
CM_ SG_ 2164752385 FW_revision_5_1 "Character 3";
CM_ SG_ 2164752385 FW_revision_6_1 "Character 3";
CM_ SG_ 2164752385 FW_revision_7_1 "Character 7";
CM_ SG_ 2164752385 FW_revision_8_1 "Character 8";
CM_ SG_ 2164752385 FW_revision_9_1 "Character 9";
CM_ SG_ 2164752385 FW_revision_10_1 "Character 10";
CM_ SG_ 2164752385 FW_revision_11_1 "Character 11";
CM_ SG_ 2164752385 FW_revision_12_1 "Character 12";
CM_ SG_ 2164752385 FW_revision_13_1 "Character 13";
CM_ SG_ 2164752385 FW_datecode_0_1 "Character 0";
CM_ SG_ 2164752385 FW_datecode_1_1 "Character 1";
CM_ SG_ 2164752385 FW_datecode_2_1 "Character 2";
CM_ SG_ 2164752385 FW_datecode_3_1 "Character 3";
CM_ SG_ 2164752385 FW_datecode_4_1 "Character 3";
CM_ SG_ 2164752385 FW_datecode_5_1 "Character 3";
CM_ SG_ 2164752385 FW_datecode_6_1 "Character 3";
CM_ SG_ 2164752385 FW_datecode_7_1 "Character 7";
CM_ SG_ 2164752385 FW_datecode_8_1 "Character 8";
CM_ SG_ 2164752385 FW_datecode_9_1 "Character 9";
CM_ SG_ 2164752385 FW_datecode_10_1 "Character 10";
CM_ SG_ 2164752385 FW_datecode_11_1 "Character 11";
CM_ SG_ 2164752385 FW_datecode_12_1 "Character 12";
CM_ SG_ 2164752385 FW_datecode_13_1 "Character 13";
CM_ SG_ 2164752397 FW_revision_0_1 "Character 0";
CM_ SG_ 2164752397 FW_revision_1_1 "Character 1";
CM_ SG_ 2164752397 FW_revision_2_1 "Character 2";
CM_ SG_ 2164752397 FW_revision_3_1 "Character 3";
CM_ SG_ 2164752397 FW_revision_4_1 "Character 3";
CM_ SG_ 2164752397 FW_revision_5_1 "Character 3";
CM_ SG_ 2164752397 FW_revision_6_1 "Character 3";
CM_ SG_ 2164752397 FW_revision_7_1 "Character 7";
CM_ SG_ 2164752397 FW_revision_8_1 "Character 8";
CM_ SG_ 2164752397 FW_revision_9_1 "Character 9";
CM_ SG_ 2164752397 FW_revision_10_1 "Character 10";
CM_ SG_ 2164752397 FW_revision_11_1 "Character 11";
CM_ SG_ 2164752397 FW_revision_12_1 "Character 12";
CM_ SG_ 2164752397 FW_revision_13_1 "Character 13";
CM_ SG_ 2164752397 FW_datecode_0_1 "Character 0";
CM_ SG_ 2164752397 FW_datecode_1_1 "Character 1";
CM_ SG_ 2164752397 FW_datecode_2_1 "Character 2";
CM_ SG_ 2164752397 FW_datecode_3_1 "Character 3";
CM_ SG_ 2164752397 FW_datecode_4_1 "Character 3";
CM_ SG_ 2164752397 FW_datecode_5_1 "Character 3";
CM_ SG_ 2164752397 FW_datecode_6_1 "Character 3";
CM_ SG_ 2164752397 FW_datecode_7_1 "Character 7";
CM_ SG_ 2164752397 FW_datecode_8_1 "Character 8";
CM_ SG_ 2164752397 FW_datecode_9_1 "Character 9";
CM_ SG_ 2164752397 FW_datecode_10_1 "Character 10";
CM_ SG_ 2164752397 FW_datecode_11_1 "Character 11";
CM_ SG_ 2164752397 FW_datecode_12_1 "Character 12";
CM_ SG_ 2164752397 FW_datecode_13_1 "Character 13";
CM_ SG_ 2164752386 Status_Error_Code_1 "Main status / error code as defined in errno/errno.h";
CM_ SG_ 2164752386 Data_1_1 "Additional information for the error/status";
CM_ SG_ 2164752386 Data_2_1 "Additional information for the error/status";
CM_ SG_ 2164752386 Data_3_1 "Additional information for the error/status";
CM_ SG_ 2164752391 Running_1 "Indicates if converter is running.";
CM_ SG_ 2164752391 PWM_1 "Indicates if converter is in PWM control mode.";
CM_ SG_ 2164752391 Current_dc_loop_mode_1 "Indicates if the current DC loop is enabled.";
CM_ SG_ 2164752391 Current_ac_loop_mode_1 "Indicates if the current AC loop is enabled.";
CM_ SG_ 2164752391 Buck_1 "Indicates if converter is in buck control mode.";
CM_ SG_ 2164752391 Boost_1 "Indicates if converter is in boost control mode.";
CM_ SG_ 2164752391 Precharge_dc_buck_mode_1 "Indicates if the precharge DC mode is enabled - buck direction.";
CM_ SG_ 2164752391 Precharge_dc_boost_mode_1 "Indicates if the precharge DC mode is enabled - boost direction.";
CM_ SG_ 2164752391 Rectifier_3ph_1 "Indicates if converter is in three-phase rectifier control mode.";
CM_ SG_ 2164752391 Stack_mode_1 "Indicates if converter is operating in stack mode.";
CM_ SG_ 2164752391 Master_1 "Indicates if converter is master in the stack.";
CM_ SG_ 2164752391 Slave_1 "Indicates if converter is slave in the stack.";
CM_ SG_ 2164752391 Inverter_1ph_1 "Indicates if converter is in single-phase inverter control mode.";
CM_ SG_ 2164752391 Boost_Neutral_1 "Indicates if converter is in boost control mode with neutral generation.";
CM_ SG_ 2164752391 Rectifier_1ph_1 "Indicates if converter is in single-phase rectifier control mode.";
CM_ SG_ 2164752391 Inverter_3ph_1 "Indicates if converter is in three-phase inverter control mode.";
CM_ SG_ 2164752391 Ready_1 "Indicates if converter is ready for operation.";
CM_ SG_ 2164752391 Inverter_1ph_Sync_1 "Single-phase inverter control mode with phase synchronization.";
CM_ SG_ 2164752391 Neutral_1 "Open-loop neutral generation.";
CM_ SG_ 2164752391 Rectifier_1ph_Buck_1 "Single-phase rectifier with buck on one leg.";
CM_ SG_ 2164752391 Inverter_1ph_Boost_1 "Single-phase inverter with boost on one leg.";
CM_ SG_ 2164752391 Rectifier_distributed_1 "Not available at the moment";
CM_ SG_ 2164752391 MPPT_buck_1 "Not available at the moment";
CM_ SG_ 2164752391 MPPT_boost_1 "Not available at the moment";
CM_ SG_ 2164752391 Buck_2p_float_1 "Buck in phases L1 and L2. Phase L3 is left floating (high impedance)";
CM_ SG_ 2164752391 Inverter_1ph_Distributed_1 "Single-phase inverter mode  distributed";
CM_ SG_ 2164752390 Protection_trip_internal_1 "This flagg is asserted if the interlock is open due to an internal fault condition (self-protection)";
CM_ SG_ 2164752390 Protection_trip_external_1 "This flag is asserted if the interlock is open due to an external condition received in the module.";
CM_ SG_ 2164752390 Phase_U_overcurrent_1 "Indicates an overcurrent event on Phase U. The overcurrent event is triggered when the measured phase current is over the programmed current limit.";
CM_ SG_ 2164752390 Phase_U_overvoltage_1 "Indicates an overvoltage event on Phase U. The overvoltage event is triggered when the measured phase voltage is over the programmed voltage limit.";
CM_ SG_ 2164752390 Phase_U_undervoltage_1 "Indicates an undervoltage event on Phase U. The overvoltage event is triggered when the measured phase voltage is over the programmed voltage limit.";
CM_ SG_ 2164752390 Phase_V_overvoltage_1 "Indicates an overvoltage event on Phase V. The overvoltage event is triggered when the measured phase voltage is over the programmed voltage limit.";
CM_ SG_ 2164752390 Phase_V_undervoltage_1 "Indicates an undervoltage event on Phase U. The overvoltage event is triggered when the measured phase voltage is over the programmed voltage limit.";
CM_ SG_ 2164752390 Phase_V_overcurrent_1 "Indicates an overcurrent event on Phase U. The overcurrent event is triggered when the measured phase current is over the programmed current limit.";
CM_ SG_ 2164752390 Phase_W_overvoltage_1 "Indicates an overvoltage event on Phase U. The overvoltage event is triggered when the measured phase voltage is over the programmed voltage limit.";
CM_ SG_ 2164752390 Phase_W_undervoltage_1 "Indicates an undervoltage event on Phase U. The overvoltage event is triggered when the measured phase voltage is over the programmed voltage limit.";
CM_ SG_ 2164752390 Phase_W_overcurrent_1 "Indicates an overcurrent event on Phase U. The overcurrent event is triggered when the measured phase current is over the programmed current limit.";
CM_ SG_ 2164752390 DC_undervoltage_1 "DC bus undervoltage condition. The undervoltage condition is asserted when the measured dc bus voltage is under the programmed voltage limit.";
CM_ SG_ 2164752390 DC_overvoltage_1 "DC bus overvoltage condition. The overvoltage condition is asserted when the measured dc bus voltage is over the programmed voltage limit.";
CM_ SG_ 2164752390 MOSFET_overtemperature_1 "This flag is asserted when the temperature of the MOSFET block is too high.";
CM_ SG_ 2164752390 Inductor_overtemperature_1 "This flag is asserted when the temperature of the inductor block is too high.";
CM_ SG_ 2164752390 Keep_Alive_not_served_1 "The Keep Alive feature is enabled but it was not served with the periodic message.";
CM_ SG_ 2164752390 PLL_not_locked_1 "Flag asserted when in rectifier modes, the PLL went out of lock condition";
CM_ SG_ 2164752390 Measurement_system_failure_1 "The voltages/currents measurement system is malfunctionning, and readouts are not guaranteed to be accurate.";
CM_ SG_ 2164752390 EEPROM_failure_1 "The configuration EEPROM failed to load or save the module configuration.";
CM_ SG_ 2164752387 Phase_U_1 "Phase current is the MOSFET loop current, in the branch U of the converter.";
CM_ SG_ 2164752387 Phase_V_1 "Phase current is the MOSFET loop current, in the branch V of the converter.";
CM_ SG_ 2164752387 Phase_W_1 "Phase current is the MOSFET loop current, in the branch W of the converter.";
CM_ SG_ 2164752400 Bus_current_1 "DC Bus current is possitive when current goes from input to output";
CM_ SG_ 2164752398 Phase_U_1 "Phase current is the MOSFET loop current, in the branch U of the converter.";
CM_ SG_ 2164752398 Phase_V_1 "Phase current is the MOSFET loop current, in the branch V of the converter.";
CM_ SG_ 2164752398 Phase_W_1 "Phase current is the MOSFET loop current, in the branch W of the converter.";
CM_ SG_ 2164752398 Stack_position_1 "Sender Stack position";
CM_ SG_ 2164752398 Group_ID_1 "Sender Group ID";
CM_ SG_ 2164752395 Phase_U_1 "RMS Phase current is the MOSFET loop current, in the branch U of the converter.";
CM_ SG_ 2164752395 Phase_V_1 "RMS Phase current is the MOSFET loop current, in the branch V of the converter.";
CM_ SG_ 2164752395 Phase_W_1 "RMS Phase current is the MOSFET loop current, in the branch W of the converter.";
CM_ SG_ 2164752396 Frequency_1 "Frequency of Three-Phase system";
CM_ SG_ 2164752396 Phase_1 "Phase of Three-Phase system";
CM_ SG_ 2164752389 Temp_Bridge_1 "Temperature of the MOSFET block";
CM_ SG_ 2164752389 Temp_Inductors_1 "Temperature of the inductors";
CM_ SG_ 2164752392 Phase_U_1 "The actual PWM duty cycle setpoint";
CM_ SG_ 2164752392 Phase_V_1 "The actual PWM duty cycle setpoint";
CM_ SG_ 2164752392 Phase_W_1 "The actual PWM duty cycle setpoint";
CM_ SG_ 2164752393 Current_setpoint_1 "The actual current setpoint";
CM_ SG_ 2164752393 Voltage_setpoint_1 "The actual voltage setpoint";
CM_ SG_ 2164752393 Frequency_setpoint_1 "The actual frequency setpoint";
CM_ SG_ 2164719712 Keep_Alive_Enable_1 "If set to 1, module will expect to receive this message every second repeatedly, or it will stop operation";
CM_ SG_ 2164719680 Converter_ON_1 "Enable the converter.";
CM_ SG_ 2164719680 PWM_ON_1 "Enable the PWM control mode.";
CM_ SG_ 2164719680 DC_Current_feedback_ON_1 "Enable the DC current loop";
CM_ SG_ 2164719680 AC_Current_feedback_ON_1 "Enable the AC current loop";
CM_ SG_ 2164719680 Buck_ON_1 "Enable the buck control mode.";
CM_ SG_ 2164719680 Boost_ON_1 "Enable the boost control mode.";
CM_ SG_ 2164719680 Rectifier_3ph_ON_1 "Enable the three-phase rectifier control mode.";
CM_ SG_ 2164719680 Inverter_1ph_ON_1 "Enable the single-phase inverter control mode.";
CM_ SG_ 2164719680 Rectifier_1ph_ON_1 "Enable the single-phase rectifier control mode.";
CM_ SG_ 2164719680 Boost_Neutral_ON_1 "Enable the boost control mode with neutral generation.";
CM_ SG_ 2164719680 Inverter_3ph_ON_1 "Enable the three-phase inverter control mode.";
CM_ SG_ 2164719680 Inverter_1ph_Sync_ON_1 "Single-phase inverter control mode with phase synchronization.";
CM_ SG_ 2164719680 Neutral_ON_1 "Open-loop neutral generation.";
CM_ SG_ 2164719680 Rectifier_1ph_Buck_ON_1 "Single-phase rectifier with buck on one leg.";
CM_ SG_ 2164719680 Inverter_1ph_Boost_ON_1 "Single-phase inverter with boost on one leg.";
CM_ SG_ 2164719680 Rectifier_Distributed_ON_1 "Single-phase (floating) distributed rectifier";
CM_ SG_ 2164719680 MPPT_buck_ON_1 "MPPT buck";
CM_ SG_ 2164719680 MPPT_boost_ON_1 "MPPT boost";
CM_ SG_ 2164719680 Buck_2p_float_ON_1 "Boost on L1 and L2. Floating L3 (high-impedance)";
CM_ SG_ 2164719680 Inverter_1ph_Distributed_ON_1 "Single-phase inverter mode distributed";
CM_ SG_ 2164719696 Clear_Interlock_1 "Clears the converter interlock";
CM_ SG_ 2164719696 Reset_Processor_1 "Reset the converter DSP";
CM_ SG_ 2164719696 Trip_Interlock_1 "Trip the inetrnal Interlock";
CM_ SG_ 2164719681 Reactive_current_setpoint_1 "This defines reactive current setpoint for 3-phase rectifier mode";
CM_ SG_ 2164719682 Phase_U_1 "The actual PWM duty cycle setpoint";
CM_ SG_ 2164719682 Phase_V_1 "The actual PWM duty cycle setpoint";
CM_ SG_ 2164719682 Phase_W_1 "The actual PWM duty cycle setpoint";
CM_ SG_ 2164719683 Current_setpoint_1 "Sets the output current setpoint. Active only when the current loop is enabled";
CM_ SG_ 2164719684 Voltage_setpoint_1 "Sets the output voltage setpoint. Active only when the voltage loop is enabled";
CM_ SG_ 2164719688 Frequency_setpoint_1 "Sets the frequency for single-phase and three-phase generator modes.";
CM_ SG_ 2164719689 Phase_setpoint_1 "Sets the phase for inverter control modes.";
CM_ SG_ 2164719685 Stack_position_1 "The converter position within the stack";
CM_ SG_ 2164719685 Stack_size_1 "How many PFC converters are in stack in total";
CM_ SG_ 2164719685 SN_number_1 "Unique module serial number";
CM_ SG_ 2164719664 Phase_voltage_min_1 "Minimum tolerated phase voltage";
CM_ SG_ 2164719664 Phase_voltage_max_1 "Maximum allowable phase voltage";
CM_ SG_ 2164719664 DC_voltage_min_1 "Minimum allowable dc voltage";
CM_ SG_ 2164719664 DC_voltage_max_1 "Maximum allowable dc voltage";
CM_ SG_ 2164719665 Phase_current_min_1 "Minimum allowable output current";
CM_ SG_ 2164719665 Phase_current_max_1 "Maximum allowable output current";
CM_ SG_ 2164719692 Group_ID_1 "Desired group ID for the device";
CM_ SG_ 2164752399 Group_ID_1 "Group ID of the device";
CM_ SG_ 2164719713 Factory_mode_1 "Customers MUST NOT USE this bit. If set to 1, module will enter in factory mode. ";
CM_ SG_ 2164719713 Silent_CAN_mode_1 "Customers MUST NOT USE this bit. If set to 1, module will enter in factory mode. ";
CM_ SG_ 2164719690 start_1 "Start automatic calibration. Multiplexer index must be 0!";
CM_ SG_ 2164719691 point_1 "Calibration point index.";
CM_ SG_ 2164719686 CRC_1 "Checksum of bytes 0 to 3, CRC-CCITT, corresponding to qChecksum (www.qt.io)";
CM_ SG_ 2164719687 CRC_1 "Checksum of bytes 0 to 3, CRC-CCITT, corresponding to qChecksum (www.qt.io)";
CM_ SG_ 2164752470 Current_U_High_1 "This flag is set if a hight current on U tripped the internal interlock";
CM_ SG_ 2164752470 Current_U_Low_1 "This flag is set if a low current on U tripped the internal interlock";
CM_ SG_ 2164752470 Current_V_High_1 "This flag is set if a hight current on V tripped the internal interlock";
CM_ SG_ 2164752470 Current_V_Low_1 "This flag is set if a low current on V tripped the internal interlock";
CM_ SG_ 2164752470 Current_W_High_1 "This flag is set if a hight current on W tripped the internal interlock";
CM_ SG_ 2164752470 Current_W_Low_1 "This flag is set if a low current on W tripped the internal interlock";
CM_ SG_ 2164752470 Voltage_DC_1 "This flag is set if a voltage on DC tripped the internal interlock";
CM_ SG_ 2164752470 Reboot_1 "This flag is set if a reboot tripped the internal interlock";
CM_ SG_ 2164752470 Unknown_1 "This flag the reason for the internal interlock is unknown";

BA_DEF_ BO_ "SystemMessageLongSymbol" STRING;

BA_ "SystemMessageLongSymbol" BO_ 2164719681 "AFE_Reactive_Current_Setpoint_Control_1";

VAL_ 2164752384 Device_type_1 7 "AFE";
VAL_ 2164752390 Protection_trip_internal_1 1 "fault";
VAL_ 2164752390 Protection_trip_external_1 1 "fault";
VAL_ 2164752390 Phase_U_overcurrent_1 1 "fault";
VAL_ 2164752390 Phase_U_overvoltage_1 1 "fault";
VAL_ 2164752390 Phase_U_undervoltage_1 1 "fault";
VAL_ 2164752390 Phase_V_overvoltage_1 1 "fault";
VAL_ 2164752390 Phase_V_undervoltage_1 1 "fault";
VAL_ 2164752390 Phase_V_overcurrent_1 1 "fault";
VAL_ 2164752390 Phase_W_overvoltage_1 1 "fault";
VAL_ 2164752390 Phase_W_undervoltage_1 1 "fault";
VAL_ 2164752390 Phase_W_overcurrent_1 1 "fault";
VAL_ 2164752390 DC_undervoltage_1 1 "fault";
VAL_ 2164752390 DC_overvoltage_1 1 "fault";
VAL_ 2164752390 MOSFET_overtemperature_1 1 "fault";
VAL_ 2164752390 Inductor_overtemperature_1 1 "fault";
VAL_ 2164752390 Keep_Alive_not_served_1 1 "fault";
VAL_ 2164752390 PLL_not_locked_1 1 "fault";
VAL_ 2164752390 NFO_1 1 "fault";
VAL_ 2164752390 Measurement_system_failure_1 1 "fault";
VAL_ 2164752390 EEPROM_failure_1 1 "fault";
VAL_ 2164752390 System_1 1 "fault";
VAL_ 2164752470 Current_U_High_1 1 "fault";
VAL_ 2164752470 Current_U_Low_1 1 "fault";
VAL_ 2164752470 Current_V_High_1 1 "fault";
VAL_ 2164752470 Current_V_Low_1 1 "fault";
VAL_ 2164752470 Current_W_High_1 1 "fault";
VAL_ 2164752470 Current_W_Low_1 1 "fault";
VAL_ 2164752470 Voltage_DC_1 1 "fault";
VAL_ 2164752470 Reboot_1 1 "fault";
VAL_ 2164752470 Unknown_1 1 "fault";
SIG_VALTYPE_ 2164752465 Current_U_1 : 1;
SIG_VALTYPE_ 2164752465 Current_V_1 : 1;
SIG_VALTYPE_ 2164752465 Current_W_1 : 1;
SIG_VALTYPE_ 2164752465 Voltage_U_1 : 1;
SIG_VALTYPE_ 2164752465 Voltage_V_1 : 1;
SIG_VALTYPE_ 2164752465 Voltage_W_1 : 1;
SIG_VALTYPE_ 2164752465 Voltage_DC_1 : 1;
SIG_VALTYPE_ 2164752466 Current_U_1 : 1;
SIG_VALTYPE_ 2164752466 Current_V_1 : 1;
SIG_VALTYPE_ 2164752466 Current_W_1 : 1;
SIG_VALTYPE_ 2164752466 Voltage_U_1 : 1;
SIG_VALTYPE_ 2164752466 Voltage_V_1 : 1;
SIG_VALTYPE_ 2164752466 Voltage_W_1 : 1;
SIG_VALTYPE_ 2164752466 Voltage_DC_1 : 1;
